# STM32N657 register map
File version: 1.0
CPU: CM55 r0p1, little endian, no MPU, FPU, vendor SysTick, 8 interrupt priority bits
Registers are 32-bit, read-write, reset 0x0 unless marked. A register's access mark holds for its fields unless they carry their own. Offsets are from the block's base; [hi:lo] are bit positions; {n}, {i} and the like mark numbered series.

## RCC (part 2 of 4) — Reset and clock control
Base 0x46028000
Same registers: RCC_S 0x56028000
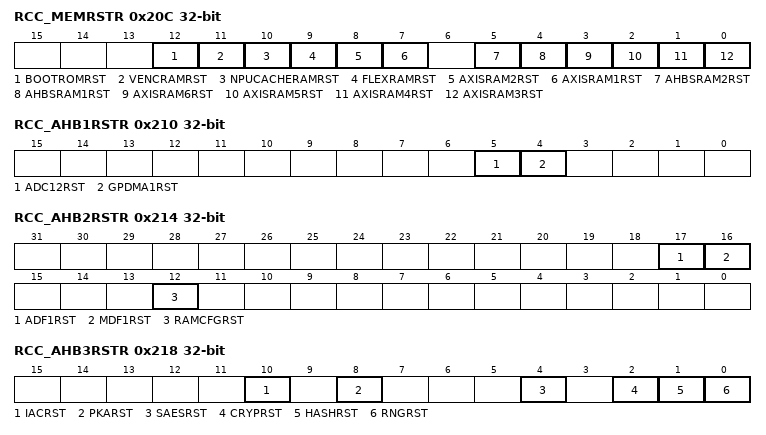
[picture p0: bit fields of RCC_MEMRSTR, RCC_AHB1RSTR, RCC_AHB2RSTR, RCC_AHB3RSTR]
0x20C RCC_MEMRSTR — RCC memories reset register
  [12] BOOTROMRST — BOOTROM reset
    0=BOOTROM is not under reset (default after reset); 1=BOOTROM is under reset
  [11] VENCRAMRST — VENCRAM reset
    0=VENCRAM is not under reset (default after reset); 1=VENCRAM is under reset
  [10] NPUCACHERAMRST — NPUCACHERAM reset
    0=NPUCACHERAM is not under reset (default after reset); 1=NPUCACHERAM is under reset
  [9] FLEXRAMRST — FLEXRAM reset
    0=FLEXRAM is not under reset (default after reset); 1=FLEXRAM is under reset
  [8] AXISRAM2RST — AXISRAM2 reset
    0=AXISRAM2 is not under reset (default after reset); 1=AXISRAM2 is under reset
  [7] AXISRAM1RST — AXISRAM1 reset
    0=AXISRAM1 is not under reset (default after reset); 1=AXISRAM1 is under reset
  [5] AHBSRAM2RST — AHBSRAM2 reset
    0=AHBSRAM2 is not under reset (default after reset); 1=AHBSRAM2 is under reset
  [4] AHBSRAM1RST — AHBSRAM1 reset
    0=AHBSRAM1 is not under reset (default after reset); 1=AHBSRAM1 is under reset
  [3] AXISRAM6RST — AXISRAM6 reset
    0=AXISRAM6 is not under reset (default after reset); 1=AXISRAM6 is under reset
  [2] AXISRAM5RST — AXISRAM5 reset
    0=AXISRAM5 is not under reset (default after reset); 1=AXISRAM5 is under reset
  [1] AXISRAM4RST — AXISRAM4reset
    0=AXISRAM4 is not under reset (default after reset); 1=AXISRAM4 is under reset
  [0] AXISRAM3RST — AXISRAM3 reset
    0=AXISRAM3 is not under reset (default after reset); 1=AXISRAM3 is under reset
0x210 RCC_AHB1RSTR — RCC AHB1 Reset register
  [5] ADC12RST — ADC12 reset
    0=ADC12 is not under reset (default after reset); 1=ADC12 is under reset
  [4] GPDMA1RST — GPDMA1 reset
    0=GPDMA1 is not under reset (default after reset); 1=GPDMA1 is under reset
0x214 RCC_AHB2RSTR — RCC AHB2 reset register
  [17] ADF1RST — ADF1 reset
    0=ADF1 is not under reset (default after reset); 1=ADF1 is under reset
  [16] MDF1RST — MDF1 reset
    0=MDF1 is not under reset (default after reset); 1=MDF1 is under reset
  [12] RAMCFGRST — RAMCFG reset
    0=RAMCFG is not under reset (default after reset); 1=RAMCFG is under reset
0x218 RCC_AHB3RSTR — RCC AHB3 reset register
  [10] IACRST — IAC reset
    0=IAC is not under reset (default after reset); 1=IAC is under reset
  [8] PKARST — PKA reset
    0=PKA is not under reset (default after reset); 1=PKA is under reset
  [4] SAESRST — SAES reset
    0=SAES is not under reset (default after reset); 1=SAES is under reset
  [2] CRYPRST — CRYP reset
    0=CRYP is not under reset (default after reset); 1=CRYP is under reset
  [1] HASHRST — HASH reset
    0=HASH is not under reset (default after reset); 1=HASH is under reset
  [0] RNGRST — RNG reset
    0=RNG is not under reset (default after reset); 1=RNG is under reset
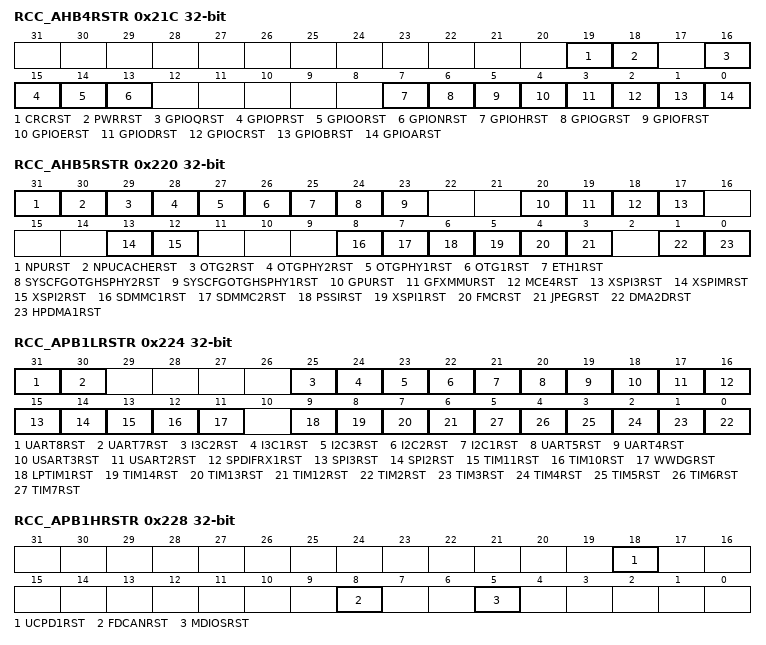
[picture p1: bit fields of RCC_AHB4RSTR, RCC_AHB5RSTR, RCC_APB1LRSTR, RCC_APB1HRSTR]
0x21C RCC_AHB4RSTR — RCC AHB4 reset register
  [19] CRCRST — CRC reset
    0=CRC is not under reset (default after reset); 1=CRC is under reset
  [18] PWRRST — PWR reset
    0=PWR is not under reset (default after reset); 1=PWR is under reset
  [16] GPIOQRST — GPIOQ reset
    0=GPIOQ is not under reset (default after reset); 1=GPIOQ is under reset
  [15] GPIOPRST — GPIOP reset
    0=GPIOP is not under reset (default after reset); 1=GPIOP is under reset
  [14] GPIOORST — GPIOO reset
    0=GPIOO is not under reset (default after reset); 1=GPIOO is under reset
  [13] GPIONRST — GPION reset
    0=GPION is not under reset (default after reset); 1=GPION is under reset
  [7] GPIOHRST — GPIOH reset
    0=GPIOH is not under reset (default after reset); 1=GPIOH is under reset
  [6] GPIOGRST — GPIOG reset
    0=GPIOG is not under reset (default after reset); 1=GPIOG is under reset
  [5] GPIOFRST — GPIOF reset
    0=GPIOF is not under reset (default after reset); 1=GPIOF is under reset
  [4] GPIOERST — GPIOE reset
    0=GPIOE is not under reset (default after reset); 1=GPIOE is under reset
  [3] GPIODRST — GPIOD reset
    0=GPIOD is not under reset (default after reset); 1=GPIOD is under reset
  [2] GPIOCRST — GPIOC reset
    0=GPIOC is not under reset (default after reset); 1=GPIOC is under reset
  [1] GPIOBRST — GPIOB reset
    0=GPIOB is not under reset (default after reset); 1=GPIOB is under reset
  [0] GPIOARST — GPIOA reset
    0=GPIOA is not under reset (default after reset); 1=GPIOA is under reset
0x220 RCC_AHB5RSTR — RCC AHB5 reset register
  [31] NPURST — NPU reset
    0=NPU is not under reset (default after reset); 1=NPU is under reset
  [30] NPUCACHERST — NPUCACHE reset
    0=NPUCACHE is not under reset (default after reset); 1=NPUCACHE is under reset
  [29] OTG2RST — OTG2 reset
    0=OTG2 is not under reset (default after reset); 1=OTG2 is under reset
  [28] OTGPHY2RST — OTGPHY2 reset
    0=OTGPHY2 is not under reset (default after reset); 1=OTGPHY2 is under reset
  [27] OTGPHY1RST — OTGPHY1 reset
    0=OTGPHY1 is not under reset (default after reset); 1=OTGPHY1 is under reset
  [26] OTG1RST — OTG1 reset
    0=OTG1 is not under reset (default after reset); 1=OTG1 is under reset
  [25] ETH1RST — ETH1 reset
    0=ETH1 is not under reset (default after reset); 1=ETH1 is under reset
  [24] SYSCFGOTGHSPHY2RST — SYSCFGOTGHSPHY2 reset
    0=SYSCFGOTGHSPHY2 is not under reset (default after reset); 1=SYSCFGOTGHSPHY2 is under reset
  [23] SYSCFGOTGHSPHY1RST — SYSCFGOTGHSPHY1 reset
    0=SYSCFGOTGHSPHY1 is not under reset (default after reset); 1=SYSCFGOTGHSPHY1 is under reset
  [20] GPURST — GPU reset
    0=GPU is not under reset (default after reset); 1=GPU is under reset
  [19] GFXMMURST — GFXMMU reset
    0=GFXMMU is not under reset (default after reset); 1=GFXMMU is under reset
  [18] MCE4RST — MCE4 reset
    0=MCE4 is not under reset (default after reset); 1=MCE4 is under reset
  [17] XSPI3RST — XSPI3 reset
    0=XSPI3 is not under reset (default after reset); 1=XSPI3 is under reset
  [13] XSPIMRST — XSPIM reset
    0=XSPIM is not under reset (default after reset); 1=XSPIM is under reset
  [12] XSPI2RST — XSPI2 reset
    0=XSPI2 is not under reset (default after reset); 1=XSPI2 is under reset
  [8] SDMMC1RST — SDMMC1 reset
    0=SDMMC1 is not under reset (default after reset); 1=SDMMC1 is under reset
  [7] SDMMC2RST — SDMMC2 reset
    0=SDMMC2 is not under reset (default after reset); 1=SDMMC2 is under reset
  [6] PSSIRST — PSSI reset
    0=PSSI is not under reset (default after reset); 1=PSSI is under reset
  [5] XSPI1RST — XSPI1 reset
    0=XSPI1 is not under reset (default after reset); 1=XSPI1 is under reset
  [4] FMCRST — FMC reset
    0=FMC is not under reset (default after reset); 1=FMC is under reset
  [3] JPEGRST — JPEG reset
    0=JPEG is not under reset (default after reset); 1=JPEG is under reset
  [1] DMA2DRST — DMA2D reset
    0=DMA2D is not under reset (default after reset); 1=DMA2D is under reset
  [0] HPDMA1RST — HPDMA1 reset
    0=HPDMA1 is not under reset (default after reset); 1=HPDMA1 is under reset
0x224 RCC_APB1LRSTR — RCC APB1L reset register
  [31] UART8RST — UART8 reset
    0=UART8 is not under reset (default after reset); 1=UART8 is under reset
  [30] UART7RST — UART7 reset
    0=UART7 is not under reset (default after reset); 1=UART7 is under reset
  [25] I3C2RST — I3C2 reset
    0=I3C2 is not under reset (default after reset); 1=I3C2 is under reset
  [24] I3C1RST — I3C1 reset
    0=I3C1 is not under reset (default after reset); 1=I3C1 is under reset
  [23] I2C3RST — I2C3 reset
    0=I2C3 is not under reset (default after reset); 1=I2C3 is under reset
  [22] I2C2RST — I2C2 reset
    0=I2C2 is not under reset (default after reset); 1=I2C2 is under reset
  [21] I2C1RST — I2C1 reset
    0=I2C1 is not under reset (default after reset); 1=I2C1 is under reset
  [20] UART5RST — UART5 reset
    0=UART5 is not under reset (default after reset); 1=UART5 is under reset
  [19] UART4RST — UART4 reset
    0=UART4 is not under reset (default after reset); 1=UART4 is under reset
  [18] USART3RST — USART3 reset
    0=USART3 is not under reset (default after reset); 1=USART3 is under reset
  [17] USART2RST — USART2 reset
    0=USART2 is not under reset (default after reset); 1=USART2 is under reset
  [16] SPDIFRX1RST — SPDIFRX1 reset
    0=SPDIFRX1 is not under reset (default after reset); 1=SPDIFRX1 is under reset
  [15] SPI3RST — SPI3 reset
    0=SPI3 is not under reset (default after reset); 1=SPI3 is under reset
  [14] SPI2RST — SPI2 reset
    0=SPI2 is not under reset (default after reset); 1=SPI2 is under reset
  [13] TIM11RST — TIM11 reset
    0=TIM11 is not under reset (default after reset); 1=TIM11 is under reset
  [12] TIM10RST — TIM10 reset
    0=TIM10 is not under reset (default after reset); 1=TIM10 is under reset
  [11] WWDGRST — WWDG reset
    0=WWDG is not under reset (default after reset); 1=WWDG is under reset
  [9] LPTIM1RST — LPTIM1 reset
    0=LPTIM1 is not under reset (default after reset); 1=LPTIM1 is under reset
  [8] TIM14RST — TIM14 reset
    0=TIM14 is not under reset (default after reset); 1=TIM14 is under reset
  [7] TIM13RST — TIM13 reset
    0=TIM13 is not under reset (default after reset); 1=TIM13 is under reset
  [6] TIM12RST — TIM12 reset
    0=TIM12 is not under reset (default after reset); 1=TIM12 is under reset
  [n-2] TIM{n}RST (n=2..7) — TIM{n} reset
    0=TIM{n} is not under reset (default after reset); 1=TIM{n} is under reset
0x228 RCC_APB1HRSTR — RCC APB1H reset register
  [18] UCPD1RST — UCPD1 reset
    0=UCPD1 is not under reset (default after reset); 1=UCPD1 is under reset
  [8] FDCANRST — FDCAN reset
    0=FDCAN is not under reset (default after reset); 1=FDCAN is under reset
  [5] MDIOSRST — MDIOS reset
    0=MDIOS is not under reset (default after reset); 1=MDIOS is under reset
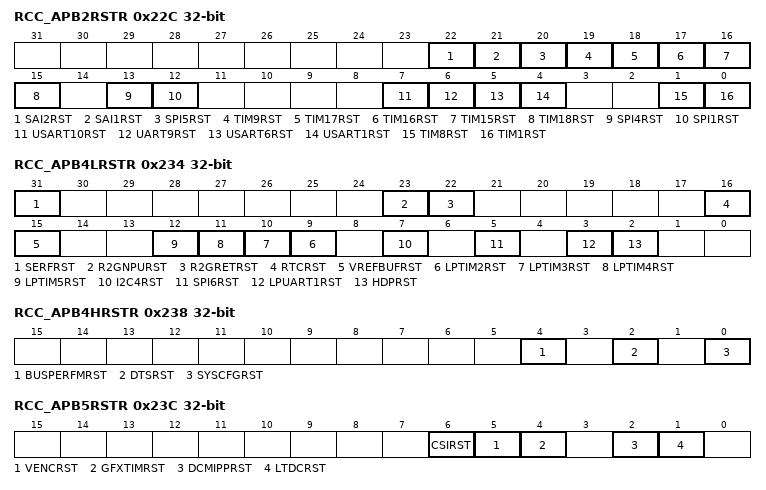
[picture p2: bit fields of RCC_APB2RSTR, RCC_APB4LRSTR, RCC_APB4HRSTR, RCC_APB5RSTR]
0x22C RCC_APB2RSTR — RCC APB2 reset register
  [22] SAI2RST — SAI2 reset
    0=SAI2 is not under reset (default after reset); 1=SAI2 is under reset
  [21] SAI1RST — SAI1 reset
    0=SAI1 is not under reset (default after reset); 1=SAI1 is under reset
  [20] SPI5RST — SPI5 reset
    0=SPI5 is not under reset (default after reset); 1=SPI5 is under reset
  [19] TIM9RST — TIM9 reset
    0=TIM9 is not under reset (default after reset); 1=TIM9 is under reset
  [18] TIM17RST — TIM17 reset
    0=TIM17 is not under reset (default after reset); 1=TIM17 is under reset
  [17] TIM16RST — TIM16 reset
    0=TIM16 is not under reset (default after reset); 1=TIM16 is under reset
  [16] TIM15RST — TIM15 reset
    0=TIM15 is not under reset (default after reset); 1=TIM15 is under reset
  [15] TIM18RST — TIM18 reset
    0=TIM18 is not under reset (default after reset); 1=TIM18 is under reset
  [13] SPI4RST — SPI4 reset
    0=SPI4 is not under reset (default after reset); 1=SPI4 is under reset
  [12] SPI1RST — SPI1 reset
    0=SPI1 is not under reset (default after reset); 1=SPI1 is under reset
  [7] USART10RST — USART10 reset
    0=USART10 is not under reset (default after reset); 1=USART10 is under reset
  [6] UART9RST — UART9 reset
    0=UART9 is not under reset (default after reset); 1=UART9 is under reset
  [5] USART6RST — USART6 reset
    0=USART6 is not under reset (default after reset); 1=USART6 is under reset
  [4] USART1RST — USART1 reset
    0=USART1 is not under reset (default after reset); 1=USART1 is under reset
  [1] TIM8RST — TIM8 reset
    0=TIM8 is not under reset (default after reset); 1=TIM8 is under reset
  [0] TIM1RST — TIM1 reset
    0=TIM1 is not under reset (default after reset); 1=TIM1 is under reset
0x234 RCC_APB4LRSTR — RCC APB4L reset register
  [31] SERFRST — SERF reset
    0=SERF is not under reset (default after reset); 1=SERF is under reset
  [23] R2GNPURST — R2GNPU reset
    0=R2GNPU is not under reset (default after reset); 1=R2GNPU is under reset
  [22] R2GRETRST — R2GRET reset
    0=R2GRET is not under reset (default after reset); 1=R2GRET is under reset
  [16] RTCRST — RTC reset
    0=RTC is not under reset (default after reset); 1=RTC is under reset
  [15] VREFBUFRST — VREFBUF reset
    0=VREFBUF is not under reset (default after reset); 1=VREFBUF is under reset
  [n+7] LPTIM{n}RST (n=2..5) — LPTIM{n} reset
    0=LPTIM{n} is not under reset (default after reset); 1=LPTIM{n} is under reset
  [7] I2C4RST — I2C4 reset
    0=I2C4 is not under reset (default after reset); 1=I2C4 is under reset
  [5] SPI6RST — SPI6 reset
    0=SPI6 is not under reset (default after reset); 1=SPI6 is under reset
  [3] LPUART1RST — LPUART1 reset
    0=LPUART1 is not under reset (default after reset); 1=LPUART1 is under reset
  [2] HDPRST — HDP reset
    0=HDP is not under reset (default after reset); 1=HDP is under reset
0x238 RCC_APB4HRSTR — RCC APB4H reset register
  [4] BUSPERFMRST — BUSPERFM reset
    0=BUSPERFM is not under reset (default after reset); 1=BUSPERFM is under reset
  [2] DTSRST — DTS reset
    0=DTS is not under reset (default after reset); 1=DTS is under reset
  [0] SYSCFGRST — SYSCFG reset
    0=SYSCFG is not under reset (default after reset); 1=SYSCFG is under reset
0x23C RCC_APB5RSTR — RCC APB5 reset register
  [6] CSIRST — CSI reset
    0=CSI is not under reset (default after reset); 1=CSI is under reset
  [5] VENCRST — VENC reset
    0=VENC is not under reset (default after reset); 1=VENC is under reset
  [4] GFXTIMRST — GFXTIM reset
    0=GFXTIM is not under reset (default after reset); 1=GFXTIM is under reset
  [2] DCMIPPRST — DCMIPP reset
    0=DCMIPP is not under reset (default after reset); 1=DCMIPP is under reset
  [1] LTDCRST — LTDC reset
    0=LTDC is not under reset (default after reset); 1=LTDC is under reset
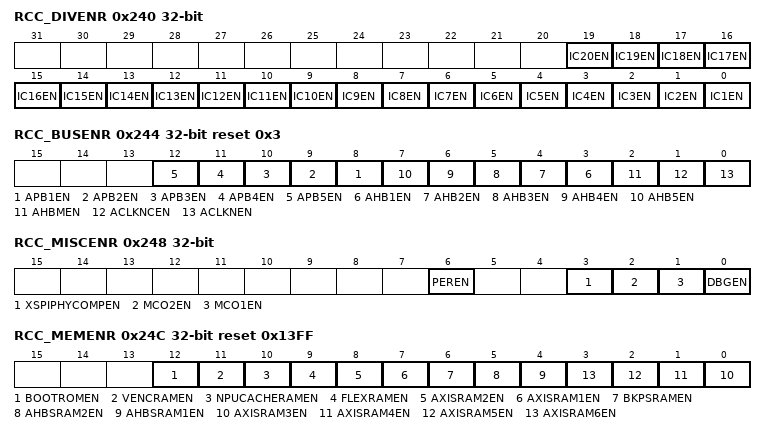
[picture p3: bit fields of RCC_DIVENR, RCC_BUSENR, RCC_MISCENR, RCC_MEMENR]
0x240 RCC_DIVENR — RCC IC dividers enable register
  [n-1] IC{n}EN (n=1..20) — IC{n} enable
    0=IC{n} is disabled (default after reset); 1=IC{n} is enabled
0x244 RCC_BUSENR reset 0x3 — RCC SoC buses enable register
  [n+7] APB{n}EN (n=1..5) — APB{n} enable
    0=APB{n} is disabled (default after reset); 1=APB{n} is enabled
  [n+2] AHB{n}EN (n=1..5) — AHB{n} enable
    0=AHB{n} is disabled (default after reset); 1=AHB{n} is enabled
  [2] AHBMEN — AHBM enable
    0=AHBM is disabled (default after reset); 1=AHBM is enabled
  [1] ACLKNCEN — ACLKNC enable
    0=ACLKNC is disabled; 1=ACLKNC is enabled (default after reset)
  [0] ACLKNEN — ACLKN enable
    0=ACLKN is disabled; 1=ACLKN is enabled (default after reset)
0x248 RCC_MISCENR — RCC miscellaneous configuration enable register
  [6] PEREN — PER enable
    0=PER is disabled (default after reset); 1=PER is enabled
  [3] XSPIPHYCOMPEN — XSPIPHYCOMP enable
    0=XSPIPHYCOMP is disabled (default after reset); 1=XSPIPHYCOMP is enabled
  [2] MCO2EN — MCO2 enable
    0=MCO2 is disabled (default after reset); 1=MCO2 is enabled
  [1] MCO1EN — MCO1 enable
    0=MCO1 is disabled (default after reset); 1=MCO1 is enabled
  [0] DBGEN — DBG enable
    0=DBG is disabled (default after reset); 1=DBG is enabled
0x24C RCC_MEMENR reset 0x13FF — RCC memory enable register
  [12] BOOTROMEN — BOOTROM enable
    0=BOOTROM is disabled; 1=BOOTROM is enabled (default after reset)
  [11] VENCRAMEN — VENCRAM enable
    0=VENCRAM is disabled (default after reset); 1=VENCRAM is enabled
  [10] NPUCACHERAMEN — NPUCACHERAM enable
    0=NPUCACHERAM is disabled (default after reset); 1=NPUCACHERAM is enabled
  [9] FLEXRAMEN — FLEXRAM enable
    0=FLEXRAM is disabled; 1=FLEXRAM is enabled (default after reset)
  [8] AXISRAM2EN — AXISRAM2 enable
    0=AXISRAM2 is disabled; 1=AXISRAM2 is enabled (default after reset)
  [7] AXISRAM1EN — AXISRAM1 enable
    0=AXISRAM1 is disabled; 1=AXISRAM1 is enabled (default after reset)
  [6] BKPSRAMEN — BKPSRAM enable
    0=BKPSRAM is disabled; 1=BKPSRAM is enabled (default after reset)
  [5] AHBSRAM2EN — AHBSRAM2 enable
    0=AHBSRAM2 is disabled; 1=AHBSRAM2 is enabled (default after reset)
  [4] AHBSRAM1EN — AHBSRAM1 enable
    0=AHBSRAM1 is disabled; 1=AHBSRAM1 is enabled (default after reset)
  [n-3] AXISRAM{n}EN (n=3..6) — AXISRAM{n} enable
    0=AXISRAM{n} is disabled; 1=AXISRAM{n} is enabled (default after reset)
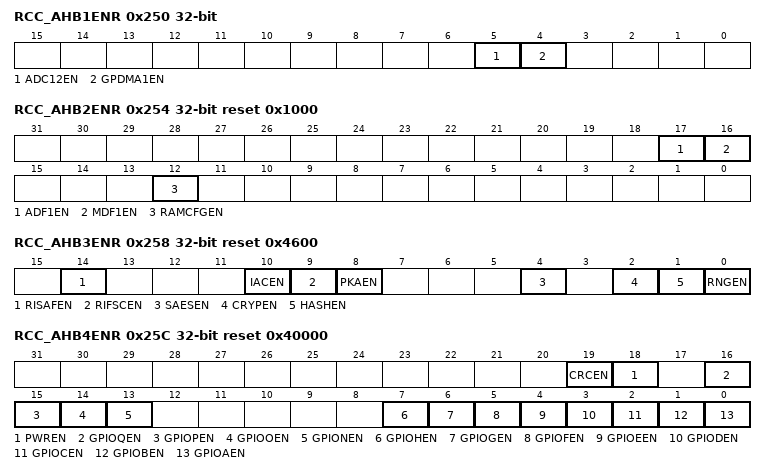
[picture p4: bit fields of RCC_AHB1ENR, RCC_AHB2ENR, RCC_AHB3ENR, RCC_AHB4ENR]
0x250 RCC_AHB1ENR — RCC AHB1 enable register
  [5] ADC12EN — ADC12 enable
    0=ADC12 is disabled (default after reset); 1=ADC12 is enabled
  [4] GPDMA1EN — GPDMA1 enable
    0=GPDMA1 is disabled (default after reset); 1=GPDMA1 is enabled
0x254 RCC_AHB2ENR reset 0x1000 — RCC AHB2 enable register
  [17] ADF1EN — ADF enable
    0=ADF is disabled (default after reset); 1=ADF is enabled
  [16] MDF1EN — MDF1 enable
    0=MDF1 is disabled (default after reset); 1=MDF1 is enabled
  [12] RAMCFGEN — RAMCFG enable
    0=RAMCFG is disabled; 1=RAMCFG is enabled (default after reset)
0x258 RCC_AHB3ENR reset 0x4600 — RCC AHB3 enable register
  [14] RISAFEN — RISAF enable
    0=RISAF is disabled; 1=RISAF is enabled (default after reset)
  [10] IACEN — IAC enable
    0=IAC is disabled; 1=IAC is enabled (default after reset)
  [9] RIFSCEN — RIFSC enable
    0=RIFSC is disabled; 1=RIFSC is enabled (default after reset)
  [8] PKAEN — PKA enable
    0=PKA is disabled (default after reset); 1=PKA is enabled
  [4] SAESEN — SAES enable
    0=SAES is disabled (default after reset); 1=SAES is enabled
  [2] CRYPEN — CRYP enable
    0=CRYP is disabled (default after reset); 1=CRYP is enabled
  [1] HASHEN — HASH enable
    0=HASH is disabled (default after reset); 1=HASH is enabled
  [0] RNGEN — RNG enable
    0=RNG is disabled (default after reset); 1=RNG is enabled
0x25C RCC_AHB4ENR reset 0x40000 — RCC AHB4 enable register
  [19] CRCEN — CRC enable
    0=CRC is disabled (default after reset); 1=CRC is enabled
  [18] PWREN — PWR enable
    0=PWR is disabled; 1=PWR is enabled (default after reset)
  [16] GPIOQEN — GPIOQ enable
    0=GPIOQ is disabled (default after reset); 1=GPIOQ is enabled
  [15] GPIOPEN — GPIOP enable
    0=GPIOP is disabled (default after reset); 1=GPIOP is enabled
  [14] GPIOOEN — GPIOO enable
    0=GPIOO is disabled (default after reset); 1=GPIOO is enabled
  [13] GPIONEN — GPION enable
    0=GPION is disabled (default after reset); 1=GPION is enabled
  [7] GPIOHEN — GPIOH enable
    0=GPIOH is disabled (default after reset); 1=GPIOH is enabled
  [6] GPIOGEN — GPIOG enable
    0=GPIOG is disabled (default after reset); 1=GPIOG is enabled
  [5] GPIOFEN — GPIOF enable
    0=GPIOF is disabled (default after reset); 1=GPIOF is enabled
  [4] GPIOEEN — GPIOE enable
    0=GPIOE is disabled (default after reset); 1=GPIOE is enabled
  [3] GPIODEN — GPIOD enable
    0=GPIOD is disabled (default after reset); 1=GPIOD is enabled
  [2] GPIOCEN — GPIOC enable
    0=GPIOC is disabled (default after reset); 1=GPIOC is enabled
  [1] GPIOBEN — GPIOB enable
    0=GPIOB is disabled (default after reset); 1=GPIOB is enabled
  [0] GPIOAEN — GPIOA enable
    0=GPIOA is disabled (default after reset); 1=GPIOA is enabled
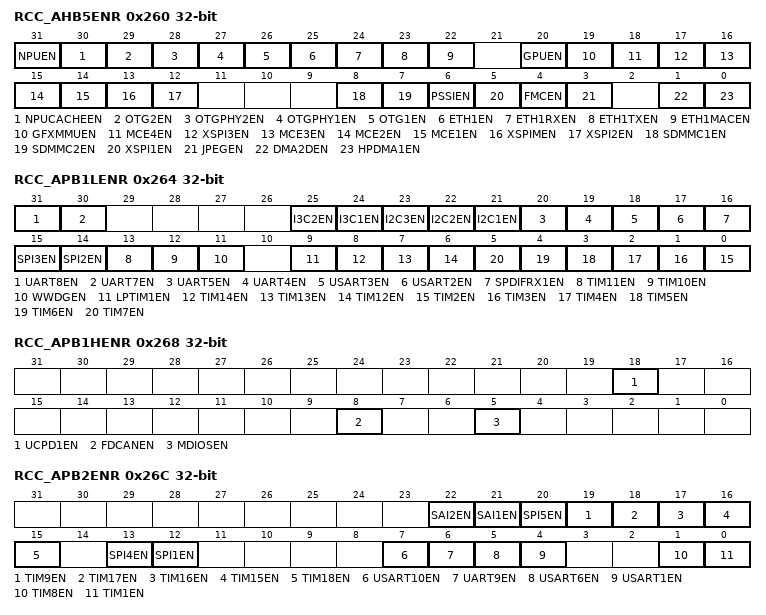
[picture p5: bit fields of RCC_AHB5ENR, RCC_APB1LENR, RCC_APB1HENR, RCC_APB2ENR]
0x260 RCC_AHB5ENR — RCC AHB5 enable register
  [31] NPUEN — NPU enable
    0=NPU is disabled (default after reset); 1=NPU is enabled
  [30] NPUCACHEEN — NPUCACHE enable
    0=NPUCACHE is disabled (default after reset); 1=NPUCACHE is enabled
  [29] OTG2EN — OTG2 enable
    0=OTG2 is disabled (default after reset); 1=OTG2 is enabled
  [28] OTGPHY2EN — OTGPHY2 enable
    0=OTGPHY2 is disabled (default after reset); 1=OTGPHY2 is enabled
  [27] OTGPHY1EN — OTGPHY1 enable
    0=OTGPHY1 is disabled (default after reset); 1=OTGPHY1 is enabled
  [26] OTG1EN — OTG1 enable
    0=OTG1 is disabled (default after reset); 1=OTG1 is enabled
  [25] ETH1EN — ETH1 enable
    0=ETH1 is disabled (default after reset); 1=ETH1 is enabled
  [24] ETH1RXEN — ETH1RX enable
    0=ETH1RX is disabled (default after reset); 1=ETH1RX is enabled
  [23] ETH1TXEN — ETH1TX enable
    0=ETH1TX is disabled (default after reset); 1=ETH1TX is enabled
  [22] ETH1MACEN — ETH1MAC enable
    0=ETH1MAC is disabled (default after reset); 1=ETH1MAC is enabled
  [20] GPUEN — GPU enable
    0=GPU is disabled (default after reset); 1=GPU is enabled
  [19] GFXMMUEN — GFXMMU enable
    0=GFXMMU is disabled (default after reset); 1=GFXMMU is enabled
  [18] MCE4EN — MCE4 enable
    0=MCE4 is disabled (default after reset); 1=MCE4 is enabled
  [17] XSPI3EN — XSPI3 enable
    0=XSPI3 is disabled (default after reset); 1=XSPI3 is enabled
  [16] MCE3EN — MCE3 enable
    0=MCE3 is disabled (default after reset); 1=MCE3 is enabled
  [15] MCE2EN — MCE2 enable
    0=MCE2 is disabled (default after reset); 1=MCE2 is enabled
  [14] MCE1EN — MCE1 enable
    0=MCE1 is disabled (default after reset); 1=MCE1 is enabled
  [13] XSPIMEN — XSPIM enable
    0=XSPIM is disabled (default after reset); 1=XSPIM is enabled
  [12] XSPI2EN — XSPI2 enable
    0=XSPI2 is disabled (default after reset); 1=XSPI2 is enabled
  [8] SDMMC1EN — SDMMC1 enable
    0=SDMMC1 is disabled (default after reset); 1=SDMMC1 is enabled
  [7] SDMMC2EN — SDMMC2 enable
    0=SDMMC2 is disabled (default after reset); 1=SDMMC2 is enabled
  [6] PSSIEN — PSSI enable
    0=PSSI is disabled (default after reset); 1=PSSI is enabled
  [5] XSPI1EN — XSPI1 enable
    0=XSPI1 is disabled (default after reset); 1=XSPI1 is enabled
  [4] FMCEN — FMC enable
    0=FMC is disabled (default after reset); 1=FMC is enabled
  [3] JPEGEN — JPEG enable
    0=JPEG is disabled (default after reset); 1=JPEG is enabled
  [1] DMA2DEN — DMA2D enable
    0=DMA2D is disabled (default after reset); 1=DMA2D is enabled
  [0] HPDMA1EN — HPDMA1 enable
    0=HPDMA1 is disabled (default after reset); 1=HPDMA1 is enabled
0x264 RCC_APB1LENR — RCC APB1L enable register
  [31] UART8EN — UART8 enable
    0=UART8 is disabled (default after reset); 1=UART8 is enabled
  [30] UART7EN — UART7 enable
    0=UART7 is disabled (default after reset); 1=UART7 is enabled
  [25] I3C2EN — I3C2 enable
    0=I3C2 is disabled (default after reset); 1=I3C2 is enabled
  [24] I3C1EN — I3C1 enable
    0=I3C1 is disabled (default after reset); 1=I3C1 is enabled
  [23] I2C3EN — I2C3 enable
    0=I2C3 is disabled (default after reset); 1=I2C3 is enabled
  [22] I2C2EN — I2C2 enable
    0=I2C2 is disabled (default after reset); 1=I2C2 is enabled
  [21] I2C1EN — I2C1 enable
    0=I2C1 is disabled (default after reset); 1=I2C1 is enabled
  [20] UART5EN — UART5 enable
    0=UART5 is disabled (default after reset); 1=UART5 is enabled
  [19] UART4EN — UART4 enable
    0=UART4 is disabled (default after reset); 1=UART4 is enabled
  [18] USART3EN — USART3 enable
    0=USART3 is disabled (default after reset); 1=USART3 is enabled
  [17] USART2EN — USART2 enable
    0=USART2 is disabled (default after reset); 1=USART2 is enabled
  [16] SPDIFRX1EN — SPDIFRX1 enable
    0=SPDIFRX1 is disabled (default after reset); 1=SPDIFRX1 is enabled
  [15] SPI3EN — SPI3 enable
    0=SPI3 is disabled (default after reset); 1=SPI3 is enabled
  [14] SPI2EN — SPI2 enable
    0=SPI2 is disabled (default after reset); 1=SPI2 is enabled
  [13] TIM11EN — TIM11 enable
    0=TIM11 is disabled (default after reset); 1=TIM11 is enabled
  [12] TIM10EN — TIM10 enable
    0=TIM10 is disabled (default after reset); 1=TIM10 is enabled
  [11] WWDGEN — WWDG enable
    0=WWDG is disabled (default after reset); 1=WWDG is enabled
  [9] LPTIM1EN — LPTIM1 enable
    0=LPTIM1 is disabled (default after reset); 1=LPTIM1 is enabled
  [8] TIM14EN — TIM14 enable
    0=TIM14 is disabled (default after reset); 1=TIM14 is enabled
  [7] TIM13EN — TIM13 enable
    0=TIM13 is disabled (default after reset); 1=TIM13 is enabled
  [6] TIM12EN — TIM12 enable
    0=TIM12 is disabled (default after reset); 1=TIM12 is enabled
  [n-2] TIM{n}EN (n=2..7) — TIM{n} enable
    0=TIM{n} is disabled (default after reset); 1=TIM{n} is enabled
0x268 RCC_APB1HENR — RCC APB1H enable register
  [18] UCPD1EN — UCPD1 enable
    0=UCPD1 is disabled (default after reset); 1=UCPD1 is enabled
  [8] FDCANEN — FDCAN enable
    0=FDCAN is disabled (default after reset); 1=FDCAN is enabled
  [5] MDIOSEN — MDIOS enable
    0=MDIOS is disabled (default after reset); 1=MDIOS is enabled
0x26C RCC_APB2ENR — RCC APB2 enable register
  [22] SAI2EN — SAI2 enable
    0=SAI2 is disabled (default after reset); 1=SAI2 is enabled
  [21] SAI1EN — SAI1 enable
    0=SAI1 is disabled (default after reset); 1=SAI1 is enabled
  [20] SPI5EN — SPI5 enable
    0=SPI5 is disabled (default after reset); 1=SPI5 is enabled
  [19] TIM9EN — TIM9 enable
    0=TIM9 is disabled (default after reset); 1=TIM9 is enabled
  [18] TIM17EN — TIM17 enable
    0=TIM17 is disabled (default after reset); 1=TIM17 is enabled
  [17] TIM16EN — TIM16 enable
    0=TIM16 is disabled (default after reset); 1=TIM16 is enabled
  [16] TIM15EN — TIM15 enable
    0=TIM15 is disabled (default after reset); 1=TIM15 is enabled
  [15] TIM18EN — TIM18 enable
    0=TIM18 is disabled (default after reset); 1=TIM18 is enabled
  [13] SPI4EN — SPI4 enable
    0=SPI4 is disabled (default after reset); 1=SPI4 is enabled
  [12] SPI1EN — SPI1 enable
    0=SPI1 is disabled (default after reset); 1=SPI1 is enabled
  [7] USART10EN — USART10 enable
    0=USART10 is disabled (default after reset); 1=USART10 is enabled
  [6] UART9EN — UART9 enable
    0=UART9 is disabled (default after reset); 1=UART9 is enabled
  [5] USART6EN — USART6 enable
    0=USART6 is disabled (default after reset); 1=USART6 is enabled
  [4] USART1EN — USART1 enable
    0=USART1 is disabled (default after reset); 1=USART1 is enabled
  [1] TIM8EN — TIM8 enable
    0=TIM8 is disabled (default after reset); 1=TIM8 is enabled
  [0] TIM1EN — TIM1 enable
    0=TIM1 is disabled (default after reset); 1=TIM1 is enabled
0x270 RCC_APB3ENR — RCC APB3 enable register
  [2] DFTEN — DFT enable
    0=DFT is disabled (default after reset); 1=DFT is enabled
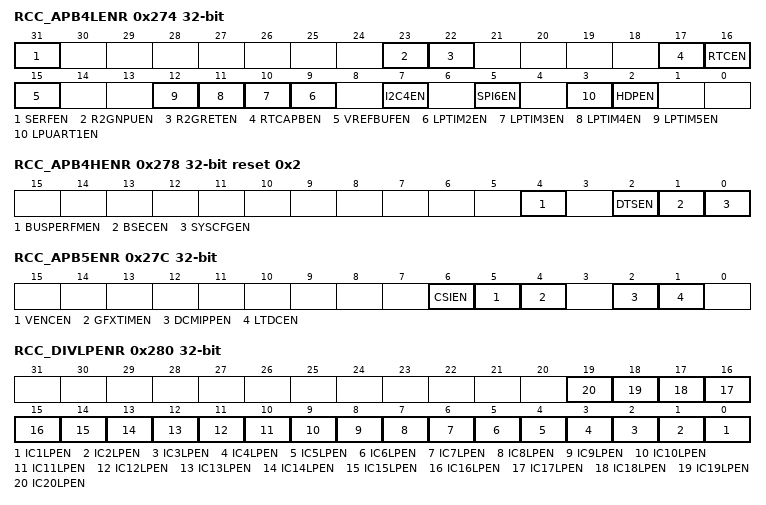
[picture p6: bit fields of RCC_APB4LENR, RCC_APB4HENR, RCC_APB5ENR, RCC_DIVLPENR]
0x274 RCC_APB4LENR — RCC APB4L enable register
  [31] SERFEN — SERF enable
    0=SERF is disabled (default after reset); 1=SERF is enabled
  [23] R2GNPUEN — R2GNPU enable
    0=R2GNPU is disabled (default after reset); 1=R2GNPU is enabled
  [22] R2GRETEN — R2GRET enable
    0=R2GRET is disabled (default after reset); 1=R2GRET is enabled
  [17] RTCAPBEN — RTCAPB enable
    0=RTCAPB is disabled (default after reset); 1=RTCAPB is enabled
  [16] RTCEN — RTC enable
    0=RTC is disabled (default after reset); 1=RTC is enabled
  [15] VREFBUFEN — VREFBUF enable
    0=VREFBUF is disabled (default after reset); 1=VREFBUF is enabled
  [n+7] LPTIM{n}EN (n=2..5) — LPTIM{n} enable
    0=LPTIM{n} is disabled (default after reset); 1=LPTIM{n} is enabled
  [7] I2C4EN — I2C4 enable
    0=I2C4 is disabled (default after reset); 1=I2C4 is enabled
  [5] SPI6EN — SPI6 enable
    0=SPI6 is disabled (default after reset); 1=SPI6 is enabled
  [3] LPUART1EN — LPUART1 enable
    0=LPUART1 is disabled (default after reset); 1=LPUART1 is enabled
  [2] HDPEN — HDP enable
    0=HDP is disabled (default after reset); 1=HDP is enabled
0x278 RCC_APB4HENR reset 0x2 — RCC APB4H enable register
  [4] BUSPERFMEN — BUSPERFM enable
    0=BUSPERFM is disabled (default after reset); 1=BUSPERFM is enabled
  [2] DTSEN — DTS enable
    0=DTS is disabled (default after reset); 1=DTS is enabled
  [1] BSECEN — BSEC enable
    0=BSEC is disabled; 1=BSEC is enabled (default after reset)
  [0] SYSCFGEN — SYSCFG enable
    0=SYSCFG is disabled (default after reset); 1=SYSCFG is enabled
0x27C RCC_APB5ENR — RCC APB5 enable register
  [6] CSIEN — CSI enable
    0=CSI is disabled (default after reset); 1=CSI is enabled
  [5] VENCEN — VENC enable
    0=VENC is disabled (default after reset); 1=VENC is enabled
  [4] GFXTIMEN — GFXTIM enable
    0=GFXTIM is disabled (default after reset); 1=GFXTIM is enabled
  [2] DCMIPPEN — DCMIPP enable
    0=DCMIPP is disabled (default after reset); 1=DCMIPP is enabled
  [1] LTDCEN — LTDC enable
    0=LTDC is disabled (default after reset); 1=LTDC is enabled
0x280 RCC_DIVLPENR — RCC dividers Sleep enable register
  [n-1] IC{n}LPEN (n=1..20) — IC{n} sleep enable
    0=IC{n} is disabled in Sleep mode (default after reset); 1=IC{n} is enabled in Sleep mode
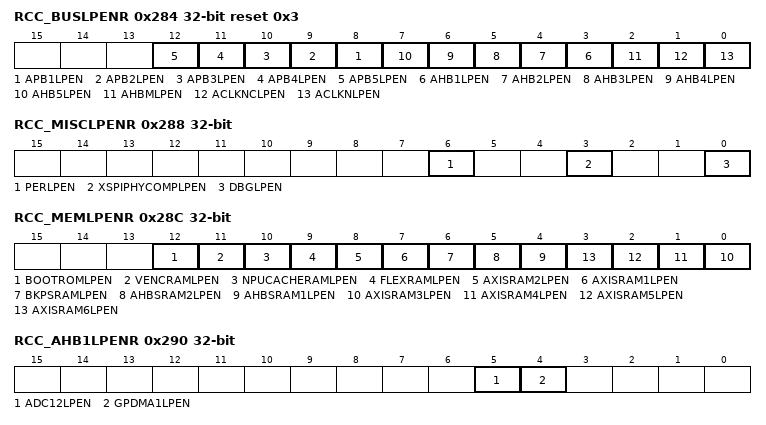
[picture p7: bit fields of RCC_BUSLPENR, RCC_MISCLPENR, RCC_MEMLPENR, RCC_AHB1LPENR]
0x284 RCC_BUSLPENR reset 0x3 — RCC SoC buses Sleep enable register
  [n+7] APB{n}LPEN (n=1..5) — APB{n} sleep enable
    0=APB{n} is disabled in Sleep mode (default after reset); 1=APB{n} is enabled in Sleep mode
  [n+2] AHB{n}LPEN (n=1..5) — AHB{n} sleep enable
    0=AHB{n} is disabled in Sleep mode (default after reset); 1=AHB{n} is enabled in Sleep mode
  [2] AHBMLPEN — AHBM sleep enable
    0=AHBM is disabled in Sleep mode (default after reset); 1=AHBM is enabled in Sleep mode
  [1] ACLKNCLPEN — ACLKNC sleep enable
    0=ACLKNC is disabled in Sleep mode; 1=ACLKNC is enabled in Sleep mode (default after reset)
  [0] ACLKNLPEN — ACLKN sleep enable
    0=ACLKN is disabled in Sleep mode; 1=ACLKN is enabled in Sleep mode (default after reset)
0x288 RCC_MISCLPENR — RCC miscellaneous configurations Sleep enable register
  [6] PERLPEN — PER sleep enable
    0=PER is disabled in Sleep mode (default after reset); 1=PER is enabled in Sleep mode
  [3] XSPIPHYCOMPLPEN — XSPIPHYCOMP sleep enable
    0=XSPIPHYCOMP is disabled in Sleep mode (default after reset); 1=XSPIPHYCOMP is enabled in Sleep mode
  [0] DBGLPEN — DBG sleep enable
    0=DBG is disabled in Sleep mode (default after reset); 1=DBG is enabled in Sleep mode
0x28C RCC_MEMLPENR — RCC memory Sleep enable register
  [12] BOOTROMLPEN — BOOTROM sleep enable
    0=BOOTROM is disabled in Sleep mode (default after reset); 1=BOOTROM is enabled in Sleep mode
  [11] VENCRAMLPEN — VENCRAM sleep enable
    0=VENCRAM is disabled in Sleep mode (default after reset); 1=VENCRAM is enabled in Sleep mode
  [10] NPUCACHERAMLPEN — NPUCACHERAM sleep enable
    0=NPUCACHERAM is disabled in Sleep mode (default after reset); 1=NPUCACHERAM is enabled in Sleep mode
  [9] FLEXRAMLPEN — FLEXRAM sleep enable
    0=FLEXRAM is disabled in Sleep mode (default after reset); 1=FLEXRAM is enabled in Sleep mode
  [8] AXISRAM2LPEN — AXISRAM2 sleep enable
    0=AXISRAM2 is disabled in Sleep mode (default after reset); 1=AXISRAM2 is enabled in Sleep mode
  [7] AXISRAM1LPEN — AXISRAM1 sleep enable
    0=AXISRAM1 is disabled in Sleep mode (default after reset); 1=AXISRAM1 is enabled in Sleep mode
  [6] BKPSRAMLPEN — BKPSRAM sleep enable
    0=BKPSRAM is disabled in Sleep mode (default after reset); 1=BKPSRAM is enabled in Sleep mode
  [5] AHBSRAM2LPEN — AHBSRAM2 sleep enable
    0=AHBSRAM2 is disabled in Sleep mode (default after reset); 1=AHBSRAM2 is enabled in Sleep mode
  [4] AHBSRAM1LPEN — AHBSRAM1 sleep enable
    0=AHBSRAM1 is disabled in Sleep mode (default after reset); 1=AHBSRAM1 is enabled in Sleep mode
  [n-3] AXISRAM{n}LPEN (n=3..6) — AXISRAM{n} sleep enable
    0=AXISRAM{n} is disabled in Sleep mode (default after reset); 1=AXISRAM{n} is enabled in Sleep mode
0x290 RCC_AHB1LPENR — RCC AHB1 Sleep enable register
  [5] ADC12LPEN — ADC12 sleep enable
    0=ADC12 is disabled in Sleep mode (default after reset); 1=ADC12 is enabled in Sleep mode
  [4] GPDMA1LPEN — GPDMA1 sleep enable
    0=GPDMA1 is disabled in Sleep mode (default after reset); 1=GPDMA1 is enabled in Sleep mode
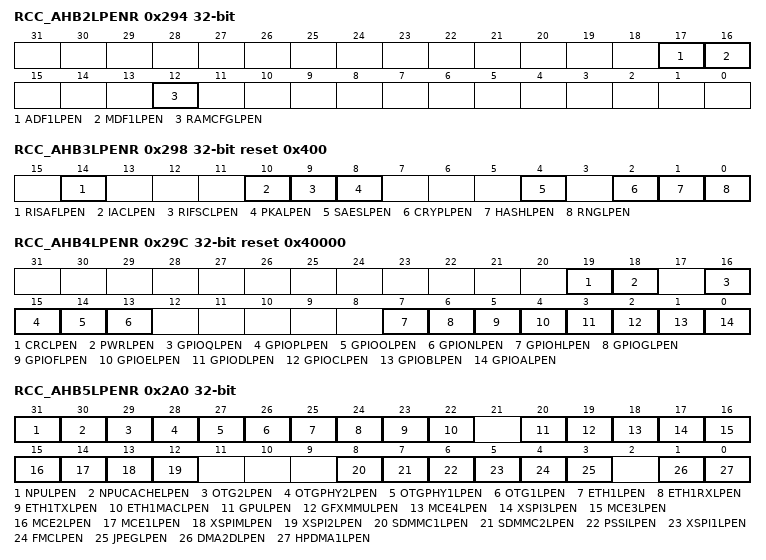
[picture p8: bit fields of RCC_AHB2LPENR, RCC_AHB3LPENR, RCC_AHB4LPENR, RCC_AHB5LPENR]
0x294 RCC_AHB2LPENR — RCC AHB2 Sleep enable register
  [17] ADF1LPEN — ADF1 sleep enable
    0=ADF1 is disabled in Sleep mode (default after reset); 1=ADF1 is enabled in Sleep mode
  [16] MDF1LPEN — MDF1 sleep enable
    0=MDF1 is disabled in Sleep mode (default after reset); 1=MDF1 is enabled in Sleep mode
  [12] RAMCFGLPEN — RAMCFG sleep enable
    0=RAMCFG is disabled in Sleep mode (default after reset); 1=RAMCFG is enabled in Sleep mode
0x298 RCC_AHB3LPENR reset 0x400 — RCC AHB3 Sleep enable register
  [14] RISAFLPEN — RISAF sleep enable
    0=RISAF is disabled in Sleep mode (default after reset); 1=RISAF is enabled in Sleep mode
  [10] IACLPEN — IAC sleep enable
    0=IAC is disabled in Sleep mode; 1=IAC is enabled in Sleep mode (default after reset)
  [9] RIFSCLPEN — RIFSC sleep enable
    0=RIFSC is disabled in Sleep mode (default after reset); 1=RIFSC is enabled in Sleep mode
  [8] PKALPEN — PKA sleep enable
    0=PKA is disabled in Sleep mode (default after reset); 1=PKA is enabled in Sleep mode
  [4] SAESLPEN — SAES sleep enable
    0=SAES is disabled in Sleep mode (default after reset); 1=SAES is enabled in Sleep mode
  [2] CRYPLPEN — CRYP sleep enable
    0=CRYP is disabled in Sleep mode (default after reset); 1=CRYP is enabled in Sleep mode
  [1] HASHLPEN — HASH sleep enable
    0=HASH is disabled in Sleep mode (default after reset); 1=HASH is enabled in Sleep mode
  [0] RNGLPEN — RNG sleep enable
    0=RNG is disabled in Sleep mode (default after reset); 1=RNG is enabled in Sleep mode
0x29C RCC_AHB4LPENR reset 0x40000 — RCC AHB4 Sleep enable register
  [19] CRCLPEN — CRC sleep enable
    0=CRC is disabled in Sleep mode (default after reset); 1=CRC is enabled in Sleep mode
  [18] PWRLPEN — PWR sleep enable
    0=PWR is disabled in Sleep mode; 1=PWR is enabled in Sleep mode (default after reset)
  [16] GPIOQLPEN — GPIOQ sleep enable
    0=GPIOQ is disabled in Sleep mode (default after reset); 1=GPIOQ is enabled in Sleep mode
  [15] GPIOPLPEN — GPIOP sleep enable
    0=GPIOP is disabled in Sleep mode (default after reset); 1=GPIOP is enabled in Sleep mode
  [14] GPIOOLPEN — GPIOO sleep enable
    0=GPIOO is disabled in Sleep mode (default after reset); 1=GPIOO is enabled in Sleep mode
  [13] GPIONLPEN — GPION sleep enable
    0=GPION is disabled in Sleep mode (default after reset); 1=GPION is enabled in Sleep mode
  [7] GPIOHLPEN — GPIOH sleep enable
    0=GPIOH is disabled in Sleep mode (default after reset); 1=GPIOH is enabled in Sleep mode
  [6] GPIOGLPEN — GPIOG sleep enable
    0=GPIOG is disabled in Sleep mode (default after reset); 1=GPIOG is enabled in Sleep mode
  [5] GPIOFLPEN — GPIOF sleep enable
    0=GPIOF is disabled in Sleep mode (default after reset); 1=GPIOF is enabled in Sleep mode
  [4] GPIOELPEN — GPIOE sleep enable
    0=GPIOE is disabled in Sleep mode (default after reset); 1=GPIOE is enabled in Sleep mode
  [3] GPIODLPEN — GPIOD sleep enable
    0=GPIOD is disabled in Sleep mode (default after reset); 1=GPIOD is enabled in Sleep mode
  [2] GPIOCLPEN — GPIOC sleep enable
    0=GPIOC is disabled in Sleep mode (default after reset); 1=GPIOC is enabled in Sleep mode
  [1] GPIOBLPEN — GPIOB sleep enable
    0=GPIOB is disabled in Sleep mode (default after reset); 1=GPIOB is enabled in Sleep mode
  [0] GPIOALPEN — GPIOA sleep enable
    0=GPIOA is disabled in Sleep mode (default after reset); 1=GPIOA is enabled in Sleep mode
0x2A0 RCC_AHB5LPENR — RCC AHB5 Sleep enable register
  [31] NPULPEN — NPU sleep enable
    0=NPU is disabled in Sleep mode (default after reset); 1=NPU is enabled in Sleep mode
  [30] NPUCACHELPEN — NPUCACHE sleep enable
    0=NPUCACHE is disabled in Sleep mode (default after reset); 1=NPUCACHE is enabled in Sleep mode
  [29] OTG2LPEN — OTG2 sleep enable
    0=OTG2 is disabled in Sleep mode (default after reset); 1=OTG2 is enabled in Sleep mode
  [28] OTGPHY2LPEN — OTGPHY2 sleep enable
    0=OTGPHY2 is disabled in Sleep mode (default after reset); 1=OTGPHY2 is enabled in Sleep mode
  [27] OTGPHY1LPEN — OTGPHY1 sleep enable
    0=OTGPHY1 is disabled in Sleep mode (default after reset); 1=OTGPHY1 is enabled in Sleep mode
  [26] OTG1LPEN — OTG1 sleep enable
    0=OTG1 is disabled in Sleep mode (default after reset); 1=OTG1 is enabled in Sleep mode
  [25] ETH1LPEN — ETH1 sleep enable
    0=ETH1 is disabled in Sleep mode (default after reset); 1=ETH1 is enabled in Sleep mode
  [24] ETH1RXLPEN — ETH1RX sleep enable
    0=ETH1RX is disabled in Sleep mode (default after reset); 1=ETH1RX is enabled in Sleep mode
  [23] ETH1TXLPEN — ETH1TX sleep enable
    0=ETH1TX is disabled in Sleep mode (default after reset); 1=ETH1TX is enabled in Sleep mode
  [22] ETH1MACLPEN — ETH1MAC sleep enable
    0=ETH1MAC is disabled in Sleep mode (default after reset); 1=ETH1MAC is enabled in Sleep mode
  [20] GPULPEN — GPU sleep enable
    0=GPU is disabled in Sleep mode (default after reset); 1=GPU is enabled in Sleep mode
  [19] GFXMMULPEN — GFXMMU sleep enable
    0=GFXMMU is disabled in Sleep mode (default after reset); 1=GFXMMU is enabled in Sleep mode
  [18] MCE4LPEN — MCE4 sleep enable
    0=MCE4 is disabled in Sleep mode (default after reset); 1=MCE4 is enabled in Sleep mode
  [17] XSPI3LPEN — XSPI3 sleep enable
    0=XSPI3 is disabled in Sleep mode (default after reset); 1=XSPI3 is enabled in Sleep mode
  [16] MCE3LPEN — MCE3 sleep enable
    0=MCE3 is disabled in Sleep mode (default after reset); 1=MCE3 is enabled in Sleep mode
  [15] MCE2LPEN — MCE2 sleep enable
    0=MCE2 is disabled in Sleep mode (default after reset); 1=MCE2 is enabled in Sleep mode
  [14] MCE1LPEN — MCE1 sleep enable
    0=MCE1 is disabled in Sleep mode (default after reset); 1=MCE1 is enabled in Sleep mode
  [13] XSPIMLPEN — XSPIM sleep enable
    0=XSPIM is disabled in Sleep mode (default after reset); 1=XSPIM is enabled in Sleep mode
  [12] XSPI2LPEN — XSPI2 sleep enable
    0=XSPI2 is disabled in Sleep mode (default after reset); 1=XSPI2 is enabled in Sleep mode
  [8] SDMMC1LPEN — SDMMC1 sleep enable
    0=SDMMC1 is disabled in Sleep mode (default after reset); 1=SDMMC1 is enabled in Sleep mode
  [7] SDMMC2LPEN — SDMMC2 sleep enable
    0=SDMMC2 is disabled in Sleep mode (default after reset); 1=SDMMC2 is enabled in Sleep mode
  [6] PSSILPEN — PSSI sleep enable
    0=PSSI is disabled in Sleep mode (default after reset); 1=PSSI is enabled in Sleep mode
  [5] XSPI1LPEN — XSPI1 sleep enable
    0=XSPI1 is disabled in Sleep mode (default after reset); 1=XSPI1 is enabled in Sleep mode
  [4] FMCLPEN — FMC sleep enable
    0=FMC is disabled in Sleep mode (default after reset); 1=FMC is enabled in Sleep mode
  [3] JPEGLPEN — JPEG sleep enable
    0=JPEG is disabled in Sleep mode (default after reset); 1=JPEG is enabled in Sleep mode
  [1] DMA2DLPEN — DMA2D sleep enable
    0=DMA2D is disabled in Sleep mode (default after reset); 1=DMA2D is enabled in Sleep mode
  [0] HPDMA1LPEN — HPDMA1 sleep enable
    0=HPDMA1 is disabled in Sleep mode (default after reset); 1=HPDMA1 is enabled in Sleep mode
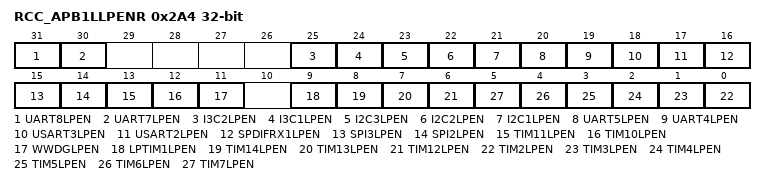
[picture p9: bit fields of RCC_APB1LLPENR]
0x2A4 RCC_APB1LLPENR — RCC APB1L Sleep enable register
  [31] UART8LPEN — UART8 sleep enable
    0=UART8 is disabled in Sleep mode (default after reset); 1=UART8 is enabled in Sleep mode
  [30] UART7LPEN — UART7 sleep enable
    0=UART7 is disabled in Sleep mode (default after reset); 1=UART7 is enabled in Sleep mode
  [25] I3C2LPEN — I3C2 sleep enable
    0=I3C2 is disabled in Sleep mode (default after reset); 1=I3C2 is enabled in Sleep mode
  [24] I3C1LPEN — I3C1 sleep enable
    0=I3C1 is disabled in Sleep mode (default after reset); 1=I3C1 is enabled in Sleep mode
  [23] I2C3LPEN — I2C3 sleep enable
    0=I2C3 is disabled in Sleep mode (default after reset); 1=I2C3 is enabled in Sleep mode
  [22] I2C2LPEN — I2C2 sleep enable
    0=I2C2 is disabled in Sleep mode (default after reset); 1=I2C2 is enabled in Sleep mode
  [21] I2C1LPEN — I2C1 sleep enable
    0=I2C1 is disabled in Sleep mode (default after reset); 1=I2C1 is enabled in Sleep mode
  [20] UART5LPEN — UART5 sleep enable
    0=UART5 is disabled in Sleep mode (default after reset); 1=UART5 is enabled in Sleep mode
  [19] UART4LPEN — UART4 sleep enable
    0=UART4 is disabled in Sleep mode (default after reset); 1=UART4 is enabled in Sleep mode
  [18] USART3LPEN — USART3 sleep enable
    0=USART3 is disabled in Sleep mode (default after reset); 1=USART3 is enabled in Sleep mode
  [17] USART2LPEN — USART2 sleep enable
    0=USART2 is disabled in Sleep mode (default after reset); 1=USART2 is enabled in Sleep mode
  [16] SPDIFRX1LPEN — SPDIFRX1 sleep enable
    0=SPDIFRX1 is disabled in Sleep mode (default after reset); 1=SPDIFRX1 is enabled in Sleep mode
  [15] SPI3LPEN — SPI3 sleep enable
    0=SPI3 is disabled in Sleep mode (default after reset); 1=SPI3 is enabled in Sleep mode
  [14] SPI2LPEN — SPI2 sleep enable
    0=SPI2 is disabled in Sleep mode (default after reset); 1=SPI2 is enabled in Sleep mode
  [13] TIM11LPEN — TIM11 sleep enable
    0=TIM11 is disabled in Sleep mode (default after reset); 1=TIM11 is enabled in Sleep mode
  [12] TIM10LPEN — TIM10 sleep enable
    0=TIM10 is disabled in Sleep mode (default after reset); 1=TIM10 is enabled in Sleep mode
  [11] WWDGLPEN — WWDG sleep enable
    0=WWDG is disabled in Sleep mode (default after reset); 1=WWDG is enabled in Sleep mode
  [9] LPTIM1LPEN — LPTIM1 sleep enable
    0=LPTIM1 is disabled in Sleep mode (default after reset); 1=LPTIM1 is enabled in Sleep mode
  [8] TIM14LPEN — TIM14 sleep enable
    0=TIM14 is disabled in Sleep mode (default after reset); 1=TIM14 is enabled in Sleep mode
  [7] TIM13LPEN — TIM13 sleep enable
    0=TIM13 is disabled in Sleep mode (default after reset); 1=TIM13 is enabled in Sleep mode
  [6] TIM12LPEN — TIM12 sleep enable
    0=TIM12 is disabled in Sleep mode (default after reset); 1=TIM12 is enabled in Sleep mode
  [n-2] TIM{n}LPEN (n=2..7) — TIM{n} sleep enable
    0=TIM{n} is disabled in Sleep mode (default after reset); 1=TIM{n} is enabled in Sleep mode
